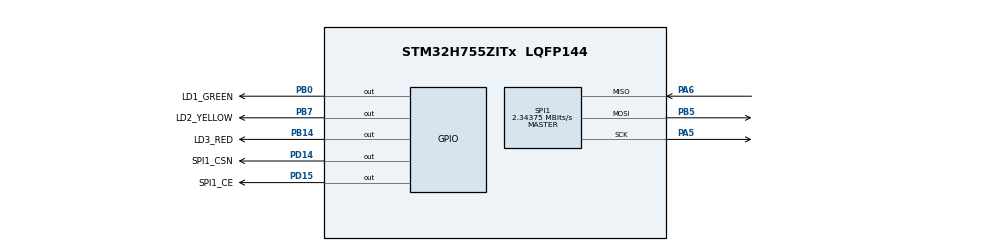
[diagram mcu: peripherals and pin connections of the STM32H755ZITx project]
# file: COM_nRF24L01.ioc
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CortexM4.IPs=CORTEX_M4\:I,DEBUG,FATFS_M4\:I,FREERTOS_M4\:I,IWDG2\:I,OPENAMP_M4\:I,PDM2PCM_M4\:I,PWR,RCC,RESMGR_UTILITY,SYS_M4\:I,USB_DEVICE_M4\:I,USB_HOST_M4\:I,VREFBUF,WWDG2\:I,GPIO,DMA,BDMA,MDMA,NVIC2\:I
CortexM7.IPs=CORTEX_M7\:I,DEBUG\:I,FATFS_M7\:I,FREERTOS_M7\:I,IWDG1\:I,OPENAMP_M7\:I,PDM2PCM_M7\:I,PWR\:I,RCC\:I,RESMGR_UTILITY\:I,SYS\:I,USB_DEVICE_M7\:I,USB_HOST_M7\:I,VREFBUF\:I,WWDG1\:I,GPIO\:I,DMA\:I,BDMA\:I,MDMA\:I,NVIC1\:I,SPI1\:I
Mcu.Family=STM32H7
Mcu.Name=STM32H755ZITx
Mcu.Package=LQFP144
NVIC1.PriorityGroup=NVIC_PRIORITYGROUP_4
NVIC2.PriorityGroup=NVIC_PRIORITYGROUP_4
PA5.Mode=Full_Duplex_Master
PA5.PinAttribute=CortexM7
PA5.Signal=SPI1_SCK
PA6.Mode=Full_Duplex_Master
PA6.PinAttribute=CortexM7
PA6.Signal=SPI1_MISO
PB0.GPIO_Label=LD1_GREEN
PB0.PinAttribute=Free
PB0.Signal=GPIO_Output
PB14.GPIO_Label=LD3_RED
PB14.PinAttribute=Free
PB14.Signal=GPIO_Output
PB5.Mode=Full_Duplex_Master
PB5.PinAttribute=CortexM7
PB5.Signal=SPI1_MOSI
PB7.GPIO_Label=LD2_YELLOW
PB7.PinAttribute=Free
PB7.Signal=GPIO_Output
PD14.GPIO_Label=SPI1_CSN
PD14.PinAttribute=Free
PD14.Signal=GPIO_Output
PD15.GPIO_Label=SPI1_CE
PD15.PinAttribute=Free
PD15.Signal=GPIO_Output
PH0-OSC_IN\ (PH0).Mode=HSE-External-Oscillator
PH0-OSC_IN\ (PH0).PinAttribute=Free
PH0-OSC_IN\ (PH0).Signal=RCC_OSC_IN
PH1-OSC_OUT\ (PH1).Mode=HSE-External-Oscillator
PH1-OSC_OUT\ (PH1).PinAttribute=Free
PH1-OSC_OUT\ (PH1).Signal=RCC_OSC_OUT
ProjectManager.HeapSize=M4-0x200,M7-0x200
ProjectManager.StackSize=M4-0x400,M7-0x400
ProjectManager.TargetToolchain=Makefile
RCC.ADCFreq_Value=16125000
RCC.APB1Freq_Value=75000000
RCC.APB2Freq_Value=75000000
RCC.APB3Freq_Value=75000000
RCC.APB4Freq_Value=75000000
RCC.CortexFreq_Value=75000000
RCC.DIVM1=1
RCC.DIVN1=18
RCC.HCLKFreq_Value=75000000
RCC.HSE_VALUE=8000000
RCC.PLLFRACN=6144
RCC.PLLSourceVirtual=RCC_PLLSOURCE_HSE
RCC.SYSCLKFreq_VALUE=75000000
RCC.SYSCLKSource=RCC_SYSCLKSOURCE_PLLCLK
RCC.USBFreq_Value=75000000
SPI1.BaudRatePrescaler=SPI_BAUDRATEPRESCALER_32
SPI1.CalculateBaudRate=2.34375 MBits/s
SPI1.Direction=SPI_DIRECTION_2LINES
SPI1.Mode=SPI_MODE_MASTER
SPI1.VirtualType=VM_MASTER
SYS.userName=SYS_M7
VP_SYS_M4_VS_Systick.Mode=SysTick
board=custom

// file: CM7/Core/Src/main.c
/* USER CODE BEGIN Header */
/**
  ******************************************************************************
  * @file           : main.c
  * @brief          : Main program body
  ******************************************************************************
  * @attention
  *
  * Copyright (c) 2023 STMicroelectronics.
  * All rights reserved.
  *
  * This software is licensed under terms that can be found in the LICENSE file
  * in the root directory of this software component.
  * If no LICENSE file comes with this software, it is provided AS-IS.
  *
  ******************************************************************************
  */
/* USER CODE END Header */
#include "main.h"

/* USER CODE BEGIN Includes */
#include "NRF24L01.h"
#include "port_settings.h"
#include "string.h"
/* USER CODE END Includes */

/* USER CODE BEGIN PD */

#ifndef HSEM_ID_0
#define HSEM_ID_0 (0U) /* HW semaphore 0*/
#endif

/* USER CODE END PD */

SPI_HandleTypeDef hspi1;

void SystemClock_Config(void);
static void MX_GPIO_Init(void);
static void MX_SPI1_Init(void);

/* USER CODE BEGIN 0 */

uint8_t TxAddress[] = {0xEE,0xDD,0xCC,0xBB,0xAA};
uint8_t TxData[] = "Hello World\n";

/* USER CODE END 0 */

int main(void)
{
/* USER CODE BEGIN Boot_Mode_Sequence_0 */
  int32_t timeout;
/* USER CODE END Boot_Mode_Sequence_0 */

/* USER CODE BEGIN Boot_Mode_Sequence_1 */
  /* Wait until CPU2 boots and enters in stop mode or timeout*/
  timeout = 0xFFFF;
  while((__HAL_RCC_GET_FLAG(RCC_FLAG_D2CKRDY) != RESET) && (timeout-- > 0));
  if ( timeout < 0 )
  {
  Error_Handler();
  }
/* USER CODE END Boot_Mode_Sequence_1 */
  /* MCU Configuration--------------------------------------------------------*/

  /* Reset of all peripherals, Initializes the Flash interface and the Systick. */
  HAL_Init();

  /* Configure the system clock */
  SystemClock_Config();
/* USER CODE BEGIN Boot_Mode_Sequence_2 */
/* When system initialization is finished, Cortex-M7 will release Cortex-M4 by means of
HSEM notification */
/*HW semaphore Clock enable*/
__HAL_RCC_HSEM_CLK_ENABLE();
/*Take HSEM */
HAL_HSEM_FastTake(HSEM_ID_0);
/*Release HSEM in order to notify the CPU2(CM4)*/
HAL_HSEM_Release(HSEM_ID_0,0);
/* wait until CPU2 wakes up from stop mode */
timeout = 0xFFFF;
while((__HAL_RCC_GET_FLAG(RCC_FLAG_D2CKRDY) == RESET) && (timeout-- > 0));
if ( timeout < 0 )
{
Error_Handler();
}
/* USER CODE END Boot_Mode_Sequence_2 */

  /* Initialize all configured peripherals */
  MX_GPIO_Init();
  MX_SPI1_Init();
  /* USER CODE BEGIN 2 */

  NRF24_Init();
  NRF24_TxMode(TxAddress, 10);

  /* USER CODE END 2 */

  /* Infinite loop */
  while (1)
  {
    if (NRF24_Transmit(TxData) == 1) {
      HAL_GPIO_TogglePin(GPIOB, GPIO_PIN_0);
    }
    HAL_Delay(1000);
  }
}

void SystemClock_Config(void)
{
  RCC_OscInitTypeDef RCC_OscInitStruct = {0};
  RCC_ClkInitTypeDef RCC_ClkInitStruct = {0};

  /** Supply configuration update enable
  */
  HAL_PWREx_ConfigSupply(PWR_DIRECT_SMPS_SUPPLY);

  /** Configure the main internal regulator output voltage
  */
  __HAL_PWR_VOLTAGESCALING_CONFIG(PWR_REGULATOR_VOLTAGE_SCALE3);

  while(!__HAL_PWR_GET_FLAG(PWR_FLAG_VOSRDY)) {}

  /** Initializes the RCC Oscillators according to the specified parameters
  * in the RCC_OscInitTypeDef structure.
  */
  RCC_OscInitStruct.OscillatorType = RCC_OSCILLATORTYPE_HSE;
  RCC_OscInitStruct.HSEState = RCC_HSE_ON;
  RCC_OscInitStruct.PLL.PLLState = RCC_PLL_ON;
  RCC_OscInitStruct.PLL.PLLSource = RCC_PLLSOURCE_HSE;
  RCC_OscInitStruct.PLL.PLLM = 1;
  RCC_OscInitStruct.PLL.PLLN = 18;
  RCC_OscInitStruct.PLL.PLLP = 2;
  RCC_OscInitStruct.PLL.PLLQ = 2;
  RCC_OscInitStruct.PLL.PLLR = 2;
  RCC_OscInitStruct.PLL.PLLRGE = RCC_PLL1VCIRANGE_3;
  RCC_OscInitStruct.PLL.PLLVCOSEL = RCC_PLL1VCOMEDIUM;
  RCC_OscInitStruct.PLL.PLLFRACN = 6144;
  if (HAL_RCC_OscConfig(&RCC_OscInitStruct) != HAL_OK)
  {
    Error_Handler();
  }

  /** Initializes the CPU, AHB and APB buses clocks
  */
  RCC_ClkInitStruct.ClockType = RCC_CLOCKTYPE_HCLK|RCC_CLOCKTYPE_SYSCLK
                              |RCC_CLOCKTYPE_PCLK1|RCC_CLOCKTYPE_PCLK2
                              |RCC_CLOCKTYPE_D3PCLK1|RCC_CLOCKTYPE_D1PCLK1;
  RCC_ClkInitStruct.SYSCLKSource = RCC_SYSCLKSOURCE_PLLCLK;
  RCC_ClkInitStruct.SYSCLKDivider = RCC_SYSCLK_DIV1;
  RCC_ClkInitStruct.AHBCLKDivider = RCC_HCLK_DIV1;
  RCC_ClkInitStruct.APB3CLKDivider = RCC_APB3_DIV1;
  RCC_ClkInitStruct.APB1CLKDivider = RCC_APB1_DIV1;
  RCC_ClkInitStruct.APB2CLKDivider = RCC_APB2_DIV1;
  RCC_ClkInitStruct.APB4CLKDivider = RCC_APB4_DIV1;

  if (HAL_RCC_ClockConfig(&RCC_ClkInitStruct, FLASH_LATENCY_1) != HAL_OK)
  {
    Error_Handler();
  }
}

static void MX_SPI1_Init(void)
{

  /* SPI1 parameter configuration*/
  hspi1.Instance = SPI1;
  hspi1.Init.Mode = SPI_MODE_MASTER;
  hspi1.Init.Direction = SPI_DIRECTION_2LINES;
  hspi1.Init.DataSize = SPI_DATASIZE_8BIT;
  hspi1.Init.CLKPolarity = SPI_POLARITY_LOW;
  hspi1.Init.CLKPhase = SPI_PHASE_1EDGE;
  hspi1.Init.NSS = SPI_NSS_SOFT;
  hspi1.Init.BaudRatePrescaler = SPI_BAUDRATEPRESCALER_16;
  hspi1.Init.FirstBit = SPI_FIRSTBIT_MSB;
  hspi1.Init.TIMode = SPI_TIMODE_DISABLE;
  hspi1.Init.CRCCalculation = SPI_CRCCALCULATION_DISABLE;
  hspi1.Init.CRCPolynomial = 10;
  // hspi1.Init.NSSPMode = SPI_NSS_PULSE_ENABLE;
  // hspi1.Init.NSSPolarity = SPI_NSS_POLARITY_LOW;
  // hspi1.Init.FifoThreshold = SPI_FIFO_THRESHOLD_01DATA;
  // hspi1.Init.TxCRCInitializationPattern = SPI_CRC_INITIALIZATION_ALL_ZERO_PATTERN;
  // hspi1.Init.RxCRCInitializationPattern = SPI_CRC_INITIALIZATION_ALL_ZERO_PATTERN;
  // hspi1.Init.MasterSSIdleness = SPI_MASTER_SS_IDLENESS_00CYCLE;
  // hspi1.Init.MasterInterDataIdleness = SPI_MASTER_INTERDATA_IDLENESS_00CYCLE;
  // hspi1.Init.MasterReceiverAutoSusp = SPI_MASTER_RX_AUTOSUSP_DISABLE;
  // hspi1.Init.MasterKeepIOState = SPI_MASTER_KEEP_IO_STATE_DISABLE;
  // hspi1.Init.IOSwap = SPI_IO_SWAP_DISABLE;
  if (HAL_SPI_Init(&hspi1) != HAL_OK)
  {
    Error_Handler();
  }

}

static void MX_GPIO_Init(void)
{
GPIO_InitTypeDef GPIO_InitStruct = {0};

  /* GPIO Ports Clock Enable */
  __HAL_RCC_GPIOH_CLK_ENABLE();
  __HAL_RCC_GPIOA_CLK_ENABLE();
  __HAL_RCC_GPIOC_CLK_ENABLE();
  __HAL_RCC_GPIOB_CLK_ENABLE();
  __HAL_RCC_GPIOD_CLK_ENABLE();

  /*Configure GPIO pin Output Level */
  HAL_GPIO_WritePin(NRF24_CE_PORT, NRF24_CE_PIN, GPIO_PIN_RESET);

  /*Configure GPIO pin : NRF_CE */
  GPIO_InitStruct.Pin = NRF24_CE_PIN;
  GPIO_InitStruct.Mode = GPIO_MODE_OUTPUT_PP;
  GPIO_InitStruct.Pull = GPIO_NOPULL;
  GPIO_InitStruct.Speed = GPIO_SPEED_FREQ_LOW;
  HAL_GPIO_Init(NRF24_CE_PORT, &GPIO_InitStruct);

  /*Configure GPIO pin Output Level */
  HAL_GPIO_WritePin(NRF24_CSN_PORT, NRF24_CSN_PIN, GPIO_PIN_RESET);

  /*Configure GPIO pin : NRF_CS */
  GPIO_InitStruct.Pin = NRF24_CSN_PIN;
  GPIO_InitStruct.Mode = GPIO_MODE_OUTPUT_PP;
  GPIO_InitStruct.Pull = GPIO_NOPULL;
  GPIO_InitStruct.Speed = GPIO_SPEED_FREQ_LOW;
  HAL_GPIO_Init(NRF24_CSN_PORT, &GPIO_InitStruct);

  /*Configure GPIO pin Output Level */
  HAL_GPIO_WritePin(GPIOB, GPIO_PIN_0|GPIO_PIN_14, GPIO_PIN_RESET);

  /*Configure GPIO pin : PB0 PB14 */
  GPIO_InitStruct.Pin = GPIO_PIN_0|GPIO_PIN_14;
  GPIO_InitStruct.Mode = GPIO_MODE_OUTPUT_PP;
  GPIO_InitStruct.Pull = GPIO_NOPULL;
  GPIO_InitStruct.Speed = GPIO_SPEED_FREQ_LOW;
  HAL_GPIO_Init(GPIOB, &GPIO_InitStruct);
}

void Error_Handler(void)
{
  /* USER CODE BEGIN Error_Handler_Debug */
  /* User can add his own implementation to report the HAL error return state */
  __disable_irq();
  while (1)
  {
    HAL_GPIO_WritePin(GPIOB, GPIO_PIN_14, 1);
  }
  /* USER CODE END Error_Handler_Debug */
}
